# MM32G0001 register map
File version: 0.9.0
CPU: CM0 r0p0, little endian, no MPU, no FPU, 2 interrupt priority bits
Registers are 32-bit, read-write, reset 0x0 unless marked. A register's access mark holds for its fields unless they carry their own. Offsets are from the block's base; [hi:lo] are bit positions; {n}, {i} and the like mark numbered series.

## GPIOB — General purpose I/O
Base 0x48000400
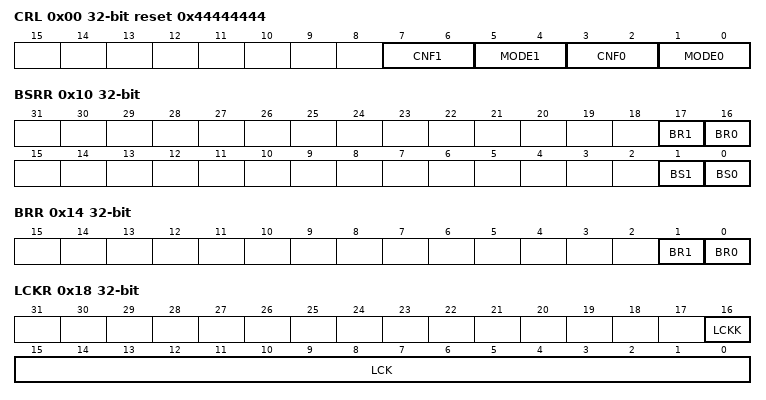
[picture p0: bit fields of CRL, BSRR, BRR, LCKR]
0x00 CRL reset 0x44444444 — configuration low register
  [7:6] CNF1 — Port 1 configuration bits
  [5:4] MODE1 — Port 1 mode bits
  [3:2] CNF0 — Port 0 configuration bits
  [1:0] MODE0 — Port 0 mode bits
0x08 IDR ro — input data register
  [15:0] IDR — Port input data
0x0C ODR — output data register
  [15:0] ODR — Port output data
0x10 BSRR wo — bit set/reset register
  [17] BR1 — Port x Reset bit 1
  [16] BR0 — Port x Reset bit 0
  [1] BS1 — Port x Set bit 1
  [0] BS0 — Port x Set bit 0
0x14 BRR wo — bit reset register
  [1] BR1 — Port x Reset bit 1
  [0] BR0 — Port x Reset bit 0
0x18 LCKR — Port configuration lock register
  [16] LCKK — Lock key
  [15:0] LCK — Port x Lock bit y
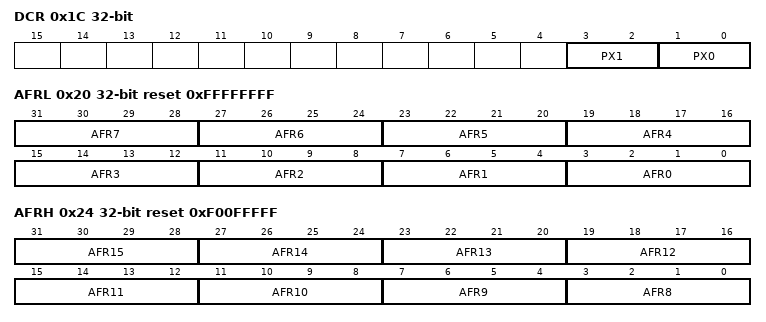
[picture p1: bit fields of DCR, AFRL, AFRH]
0x1C DCR — Port output open drain control register
  [3:2] PX1, [1:0] PX0
0x20 AFRL reset 0xFFFFFFFF — Port Multiplexing Function Low Register
  [4n+3:4n] AFR{n} (n=0..7) — Multiplexing function selection for bit {n} of portx
0x24 AFRH reset 0xF00FFFFF — Port Multiplexing Function High Register
  [4n-29:4n-32] AFR{n} (n=8..15) — Multiplexing function selection for bit {n} of portx

## IWDG — Independent watchdog
Base 0x40003000
0x00 KR wo — Key register
  [15:0] KEY — Key value
0x04 PR — Prescaler register
  [2:0] PR — Prescaler divider
0x08 RLR reset 0xFFF — Reload register
  [11:0] RL — Watchdog counter reload value
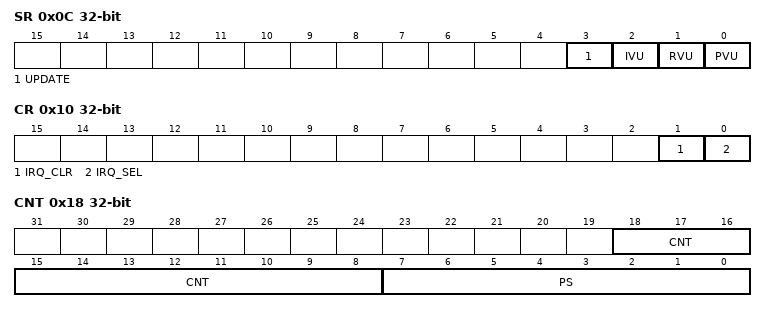
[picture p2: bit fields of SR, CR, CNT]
0x0C SR ro — Status register
  [3] UPDATE — Watchdog Reloads Update Flag
  [2] IVU — Watchdog interrupt generate value update
  [1] RVU — Watchdog counter reload value update
  [0] PVU — Watchdog prescaler value update
0x10 CR — Control register
  [1] IRQ_CLR — Interruput clear
  [0] IRQ_SEL — Interruput select
0x14 IGEN — Interruput generate value register
  [11:0] IGEN — Watchdog Interrupt Generate value
0x18 CNT — Counter
  [18:8] CNT — Current value of watchdog counter
  [7:0] PS — Watchdog prescaler counter value

## PWR — Power control
Base 0x40007000
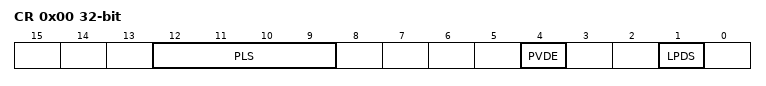
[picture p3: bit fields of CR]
0x00 CR
  [12:9] PLS — PVD level selection
  [4] PVDE — Power voltage detector enable
  [1] LPDS — Power down deepsleep
0x04 CSR
  [2] PVDO — PVD output

## RCC — Reset and clock control
Base 0x40021000
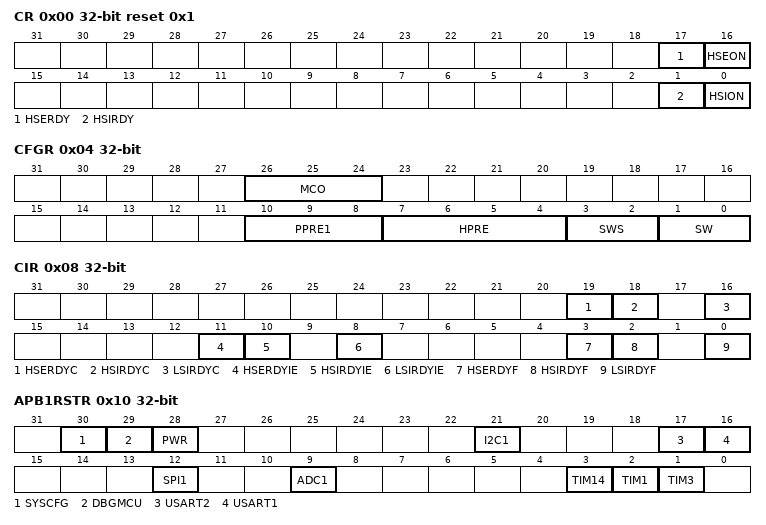
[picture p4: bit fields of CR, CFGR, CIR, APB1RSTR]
0x00 CR reset 0x1 — Control Register
  [17] HSERDY — External high-speed clock ready flag
  [16] HSEON — Internal high-speed clock enable
  [1] HSIRDY — Internal high-speed clock ready flag
  [0] HSION — Internal high-speed clock enable
0x04 CFGR — Configuration Register
  [26:24] MCO — Microcontroller clock output
  [10:8] PPRE1 — APB low-speed prescaler(APB1)
  [7:4] HPRE — AHB Prescaler
  [3:2] SWS — System clock switch status
  [1:0] SW — System clock switch
0x08 CIR — Clock Interrupt Register
  [19] HSERDYC — HSE ready interrupt clear
  [18] HSIRDYC — HSI ready interrupt clear
  [16] LSIRDYC — LSI ready interrupt clear
  [11] HSERDYIE — HSE ready interrupt enable
  [10] HSIRDYIE — HSI ready interrupt enable
  [8] LSIRDYIE — LSI ready interrupt enable
  [3] HSERDYF — HSE ready interrupt flag
  [2] HSIRDYF — HSI ready interrupt flag
  [0] LSIRDYF — LSI ready interrupt flag
0x10 APB1RSTR — Advanced Peripheral Bus 1 Reset Register
  [30] SYSCFG — SYSCFG reset
  [29] DBGMCU — DBGMCU reset
  [28] PWR — Power interface reset
  [21] I2C1 — I2C1 reset
  [17] USART2 — UART2 reset
  [16] USART1 — UART1 reset
  [12] SPI1 — SPI1 reset
  [9] ADC1 — ADC1 reset
  [3] TIM14 — TIM14 reset
  [2] TIM1 — TIM1 reset
  [1] TIM3 — TIM3 reset
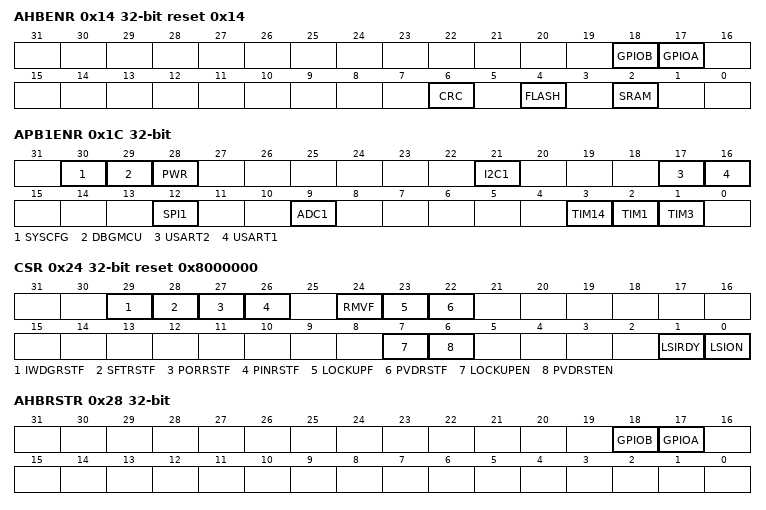
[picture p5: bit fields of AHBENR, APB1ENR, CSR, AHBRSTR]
0x14 AHBENR reset 0x14 — Advanced High Performance Bus Enable Register
  [18] GPIOB — I/O port B clock enable
  [17] GPIOA — I/O port A clock enable
  [6] CRC — CRC clock enable
  [4] FLASH — FLASH clock enable
  [2] SRAM — SRAM interface clock enable
0x1C APB1ENR — Advanced Peripheral Bus 1 Enable Register
  [30] SYSCFG — SYSCFG enable
  [29] DBGMCU — DBGMCU enable
  [28] PWR — Power interface enable
  [21] I2C1 — I2C1 enable
  [17] USART2 — UART2 enable
  [16] USART1 — UART1 enable
  [12] SPI1 — SPI1 enable
  [9] ADC1 — ADC1 enable
  [3] TIM14 — TIM14 enable
  [2] TIM1 — TIM1 enable
  [1] TIM3 — TIM3 enable
0x24 CSR reset 0x8000000 — Control Status Register
  [29] IWDGRSTF — Independent watchdog reset flag
  [28] SFTRSTF — Software reset flag
  [27] PORRSTF — POR/PDR reset flag
  [26] PINRSTF — PIN reset flag
  [24] RMVF — Remove reset flag
  [23] LOCKUPF — CPU lockup reset flag
  [22] PVDRSTF — PVD reset flag
  [7] LOCKUPEN — CPU lockup reset enable
  [6] PVDRSTEN — PVD reset enable
  [1] LSIRDY — Internal low-speed oscillator ready
  [0] LSION — Internal low-speed oscillator enable
0x28 AHBRSTR — Advanced High Performance Bus Reset Register
  [18] GPIOB — I/O port B clock reset
  [17] GPIOA — I/O port A clock reset
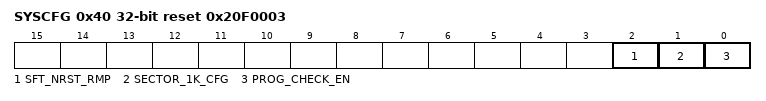
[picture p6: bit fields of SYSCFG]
0x40 SYSCFG reset 0x20F0003 — System Configuration Register
  [2] SFT_NRST_RMP — Software mapping NRST
  [1] SECTOR_1K_CFG — The size of flash page erase
  [0] PROG_CHECK_EN — Whether to check if the data in Flash is 0xFF when writing Flash
